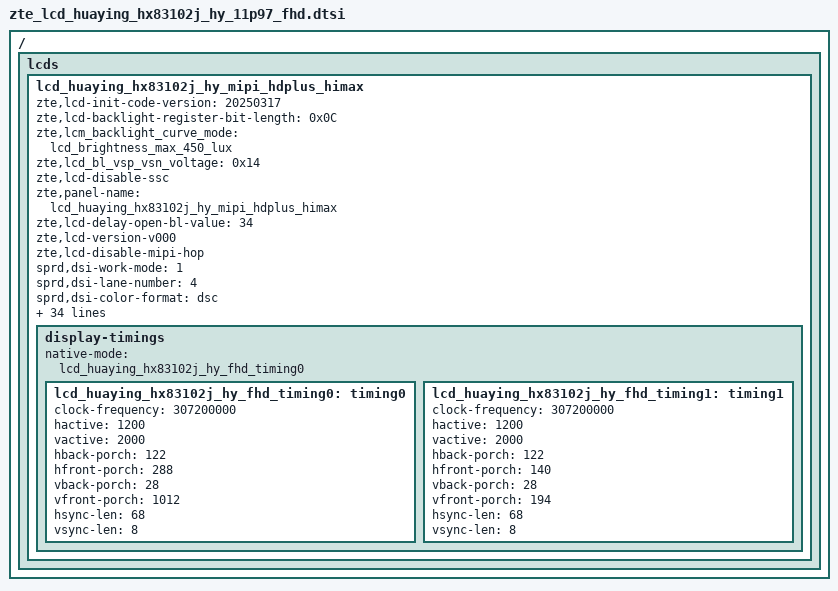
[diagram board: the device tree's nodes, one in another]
/ {
	fragment {
		target-path = "/";
		__overlay__ {
			lcds {
				lcd_huaying_hx83102j_hy_mipi_hdplus_himax: lcd_huaying_hx83102j_hy_mipi_hdplus_himax {
					zte,lcd-init-code-version = "20250317";

					zte,lcd-backlight-register-bit-length = <0x0C>;
					zte,lcm_backlight_curve_mode = "lcd_brightness_max_450_lux";
					zte,lcd_bl_vsp_vsn_voltage = <0x14>;
					zte,lcd-disable-ssc;
					zte,panel-name = "lcd_huaying_hx83102j_hy_mipi_hdplus_himax";
					zte,lcd-delay-open-bl-value = <34>;
					zte,lcd-version-v000;
					zte,lcd-disable-mipi-hop;

					sprd,dsi-work-mode = <1>;
					sprd,dsi-lane-number = <4>;
					sprd,dsi-color-format = "dsc";
					sprd,dpi-clk-div = <0>;
					sprd,video-lp-cmd-enable = <1>;
					sprd,video-lp-en-mode = <3>;
					sprd,hporch-lp-disable = <0>;
					sprd,vrr-enabled;
					sprd,vrr-max-layers = <3>;
					sprd,slice-width = <600>;
					sprd,slice-height = <40>;
					sprd,output-bpc = <8>;
					sprd,dsc-enable = <1>;
					sprd,dual-dsi-enable = <0>;

					sprd,phy-bit-clock = <896000>;
					sprd,phy-escape-clock = <20000>;/* kHz */

					sprd,width-mm = <15642>;
					sprd,height-mm = <26070>;

					sprd,esd-check-enable = <1>;/* 0:close , 1:open */
					sprd,esd-check-mode = <1>;/* 0:REG ,1:TE  */
					sprd,esd-check-period = <2000>;
					sprd,esd-check-register = <0x0A>;
					sprd,esd-check-value = <0x9C>;

					sprd,dphy-taget-val = <5>;

					sprd,reset-on-sequence = <1 5>, <0 2>, <1 50>;
					sprd,reset-off-sequence = <1 20>;

					sprd,use-gen-write;
					sprd,initial-command = [
						39 00 00 06 B9 83 10 21 55 00
						15 00 00 02 E9 C4
						15 00 00 02 D9 D4
						15 00 00 02 E9 3F
						39 00 00 1B B1 2C B5 B5 31 F1 42 E1 43 36
											36 36 36 1A 8B 11 65 00 88 FA
											FF FF 8F FF 08 98 33
						39 00 00 10 B2 00 47 B0 D0 00 22 C0 3C 55
											00 00 00 00 88 F5
						39 00 00 12 B4 38 38 3D 38 38 38 00 40 58
											4C 01 57 01 00 03 05 00
						15 00 00 02 B8 40
						15 00 00 02 E9 CD
						15 00 00 02 BA 84
						15 00 00 02 E9 3F
						39 00 00 03 BC 1B 04
						15 00 00 02 BE 20
						39 00 00 09 BF FC C4 80 9C 36 00 0D 04
						39 00 00 0B C0 3B 3B 22 11 22 A0 61 08 F5 03
						39 00 00 04 C2 43 FF 00
						39 00 00 15 C7 0D 83 14 AF 24 89 00 00 BE
											00 60 80 03 B2 04 60 10 80 22 40
						15 00 00 02 E9 C6
						15 00 00 02 C8 97
						15 00 00 02 E9 3F
						39 00 00 06 C9 00 1E 13 88 01
						39 00 00 07 CB 08 13 07 00 09 57
						39 00 00 04 CC 02 03 4C
						15 00 00 02 E9 C4
						15 00 00 02 D0 03
						15 00 00 02 E9 3F
						39 00 00 08 D1 07 06 00 02 04 2C FF
						39 00 00 23 D3 06 00 00 00 00 04 08 04 08
											27 47 74 37 20 20 03 03 32 10
											1A 00 1B 32 17 F5 07 F6 32 10
											08 00 08 00 00
						39 00 00 2D D5 25 25 24 24 18 18 18 18 18
											18 1E 1E 1F 1F 18 18 00 00 01
											01 02 02 03 03 04 04 05 05 06
											06 07 07 21 21 20 20 18 18 18
											18 18 18 18 18
						39 00 00 25 D8 00 00 00 00 00 00 00 00 00
											00 00 00 00 00 00 00 00 00 00
											00 00 00 00 00 00 00 00 00 00
											00 00 00 00 00 00 00
						39 00 00 2F E0 00 09 15 1E 26 44 5D 63 68
											63 7B 7E 81 8E 89 8E 95 A6 A4
											51 58 64 73 00 09 15 1E 26 44
											5D 63 68 63 7B 7E 81 8E 89 8E
											95 A6 A4 51 58 64 73
						39 00 00 02 BD 00
						39 00 00 02 C1 01
						39 00 00 02 BD 01
						39 00 00 3B C1 00 04 08 0C 10 14 18 1C 20
												24 28 2C 30 34 39 3D 41 45 49
												4C 55 5D 64 6C 74 7C 84 8B 93
												9C A3 AC B4 BB C4 CC D4 DC E4
												EC F4 F8 FA FC FE FF 11 99 EB
												E1 53 0E 93 CC B3 5E 54 00
						39 00 00 02 BD 02
						39 00 00 3B C1 00 04 08 0C 10 14 18 1C 20
												24 28 2C 30 34 39 3D 41 45 49
												4C 55 5D 64 6C 74 7C 84 8B 93
												9C A3 AC B4 BB C4 CC D4 DC E4
												EC F4 F8 FA FC FE FF 11 99 EB
												E1 53 0E 93 CC B3 5E 54 00
						39 00 00 02 BD 03
						39 00 00 3B C1 00 04 07 0B 0F 13 17 1A 1E
												22 26 2A 2D 31 35 39 3D 41 45
												48 4F 57 5E 66 6D 75 7C 83 8B
												92 9A A1 A9 B1 B8 BF C7 CF D6
												DE E6 E9 EB ED EF F0 0A 83 E4
												E6 92 ED 8B 26 07 99 29 00
						39 00 00 02 BD 00
						39 00 00 2E E1 11 00 00 89 30 80 07 D0 02
											58 00 28 02 58 02 58 02 00 02
											2C 00 20 04 12 00 08 00 0C 02
											77 02 4A 18 00 10 F0 03 0C 20
											00 06 0B 0B 33 0E
						39 00 00 1A E7 0A 0E 0E 2D 3C 57 00 4E A7
											14 14 00 00 00 00 F0 07 01 02
											00 33 03 84 18 01
						15 00 00 02 BD 01
						39 00 00 05 B1 01 7F 11 FD
						15 00 00 02 CB 86
						15 00 00 02 E9 C5
						39 00 00 08 D3 00 00 00 80 80 0C 81
						15 00 00 02 E9 3F
						39 00 00 25 D8 00 00 00 00 00 00 00 00 00
											00 00 00 00 00 00 00 00 00 00
											00 00 00 00 00 00 00 00 00 00
											00 00 00 00 00 00 00
						39 00 00 1A E1 40 09 BE 19 FC 19 FA 19 F8
											1A 38 1A 78 1A B6 2A F6 2B 34
											2B 74 3B 74 6B F4
						39 00 00 39 E2 5A 66 70 5A 5A 5A 16 4A 58
											4C 04 68 01 69 03 05 20 01 03
											00 00 0F 0F 0F 0F 00 00 00 0F
											10 10 32 36 69 02 4E A7 14 14
											00 00 6F 01 BB 0F B5 10 00 20
											69 00 61 00 0A 40 00
						39 00 00 0E E7 02 00 38 01 A2 0D 14 0E A0
											00 00 20 40
						15 00 00 02 BD 02
						39 00 00 06 CB 03 07 00 0A 1E
						15 00 00 02 BF F2
						39 00 00 0D D8 FF FE FF FF FA B0 FF FE FF FF FA B0
						39 00 00 24 E7 FF 04 FF 04 FF 04 03 03 03
											25 00 25 81 02 40 00 20 57 04
											03 02 01 00 00 00 00 01 00 00
											00 00 00 00 00 02
						15 00 00 02 BD 03
						15 00 00 02 E9 C6
						39 00 00 04 B4 03 FF F8
						15 00 00 02 E9 3F
						39 00 00 19 D8 AA AA AA AA AA A0 AA AA AA
											AA AA A0 FF FE FF FF FA B0 FF
											FE FF FF FA B0
						15 00 00 02 E1 01
						15 00 00 02 BD 00
						15 00 00 02 E9 C4
						15 00 00 02 BA 96
						15 00 00 02 E9 3F
						15 00 00 02 BD 01
						15 00 00 02 E9 C5
						15 00 00 02 BA 4F
						15 00 00 02 E9 3F
						15 00 00 02 BD 00
						15 00 00 02 E2 10

						39 00 00 02 35 00
						39 00 00 05 B9 00 00 00 00
						05 64 00 01 11
						05 14 00 01 29
					];
					zte,fps90-to-fps60 = [
						39 00 00 06 B9 83 10 21 55 00
						15 00 00 02 E2 10
						39 00 00 05 B9 00 00 00 00
					];
					zte,fps60-to-fps90 = [
						39 00 00 06 B9 83 10 21 55 00
						15 00 00 02 E2 00
						39 00 00 05 B9 00 00 00 00
					];
					sprd,sleep-in-command = [
						15 01 00 02 AC 0A
						39 14 00 03 28 00 00
						39 78 00 03 10 00 00
						];
					sprd,sleep-out-command = [
						05 78 00 01 11
						05 14 00 01 29
						];
					display-timings {
						native-mode = <&lcd_huaying_hx83102j_hy_fhd_timing0>;
						lcd_huaying_hx83102j_hy_fhd_timing0: timing0 {
							clock-frequency = <307200000>;
							hactive = <1200>;
							vactive = <2000>;
							hback-porch = <122>;
							hfront-porch = <288>;
							vback-porch = <28>;
							vfront-porch = <1012>;
							hsync-len = <68>;
							vsync-len = <8>;
						};
						lcd_huaying_hx83102j_hy_fhd_timing1: timing1 {
							clock-frequency = <307200000>;
							hactive = <1200>;
							vactive = <2000>;
							hback-porch = <122>;
							hfront-porch = <140>;
							vback-porch = <28>;
							vfront-porch = <194>;
							hsync-len = <68>;
							vsync-len = <8>;
						};
					};
				};
			};
		};
	};
};
